AUTOSAR XML (schema 00048)
package /ComponentTypes
  swc implementation SecOc_Server_Implementation: behavior=SecOc_Server_InternalBehavior
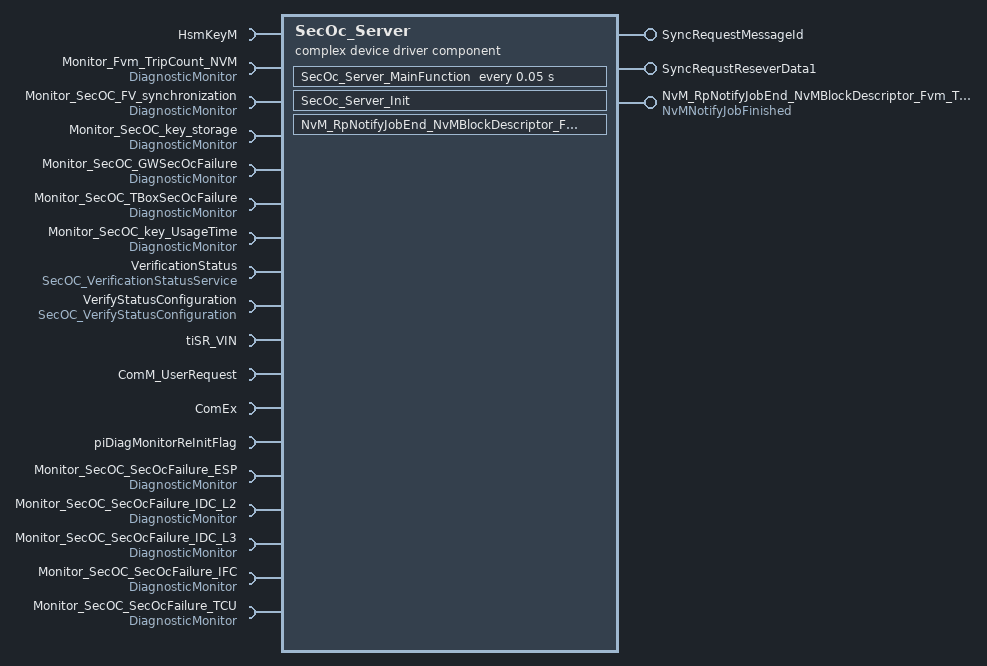
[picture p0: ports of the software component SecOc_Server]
  complex device driver sw component type SecOc_Server
    require port HsmKeyM: required-com-specs=[SetCmacKey, SetAes128Key, GetCmacKeyState, GetCmacKey, GetAes128Key], required-interface=HsmKeyM
    provide port SyncRequestMessageId: nonqueued-sender-com-spec{data-element=SyncRequestMessageId, init-value=17}, provided-interface=SyncRequestMessageId
    provide port SyncRequstReseverData1: nonqueued-sender-com-spec{data-element=SyncRequstReseverData1, init-value=7 x 0}, provided-interface=SyncRequstReseverData1
    require port Monitor_Fvm_TripCount_NVM: required-interface=DiagnosticMonitor
      required-com-specs:
        GetEventExtendedDataRecordEx
        GetEventFreezeFrameDataEx
        GetFaultDetectionCounter
        GetDTCOfEvent
        GetEventTested
        GetEventFailed
        GetEventStatus
        GetEventUdsStatus
        ResetEventDebounceStatus
        ResetEventStatus
        SetEventStatus
    provide port NvM_RpNotifyJobEnd_NvMBlockDescriptor_Fvm_TripCount: server-com-spec{operation=JobFinished, queue-length=1}, provided-interface=NvMNotifyJobFinished
    16 x require port:
      Monitor_SecOC_FV_synchronization: required-interface=DiagnosticMonitor
        required-com-specs:
          GetEventExtendedDataRecordEx
          GetEventFreezeFrameDataEx
          GetFaultDetectionCounter
          GetDTCOfEvent
          GetEventTested
          GetEventFailed
          GetEventStatus
          GetEventUdsStatus
          ResetEventDebounceStatus
          ResetEventStatus
          SetEventStatus
      Monitor_SecOC_key_storage: required-interface=DiagnosticMonitor
        required-com-specs:
          GetEventExtendedDataRecordEx
          GetEventFreezeFrameDataEx
          GetFaultDetectionCounter
          GetDTCOfEvent
          GetEventTested
          GetEventFailed
          GetEventStatus
          GetEventUdsStatus
          ResetEventDebounceStatus
          ResetEventStatus
          SetEventStatus
      Monitor_SecOC_GWSecOcFailure: required-interface=DiagnosticMonitor
        required-com-specs:
          GetEventExtendedDataRecordEx
          GetEventFreezeFrameDataEx
          GetFaultDetectionCounter
          GetDTCOfEvent
          GetEventTested
          GetEventFailed
          GetEventStatus
          GetEventUdsStatus
          ResetEventDebounceStatus
          ResetEventStatus
          SetEventStatus
      Monitor_SecOC_TBoxSecOcFailure: required-interface=DiagnosticMonitor
        required-com-specs:
          GetEventExtendedDataRecordEx
          GetEventFreezeFrameDataEx
          GetFaultDetectionCounter
          GetDTCOfEvent
          GetEventTested
          GetEventFailed
          GetEventStatus
          GetEventUdsStatus
          ResetEventDebounceStatus
          ResetEventStatus
          SetEventStatus
      Monitor_SecOC_key_UsageTime: required-interface=DiagnosticMonitor
        required-com-specs:
          GetEventExtendedDataRecordEx
          GetEventFreezeFrameDataEx
          GetFaultDetectionCounter
          GetDTCOfEvent
          GetEventTested
          GetEventFailed
          GetEventStatus
          GetEventUdsStatus
          ResetEventDebounceStatus
          ResetEventStatus
          SetEventStatus
      VerificationStatus: nonqueued-receiver-com-spec=data-element=verificationStatus, required-interface=SecOC_VerificationStatusService
      VerifyStatusConfiguration: client-com-spec=VerifyStatusOverride, required-interface=SecOC_VerifyStatusConfiguration
      tiSR_VIN: nonqueued-receiver-com-spec{data-element=Element, filter=data-filter-type=ALWAYS, init-value=17 x 0}, required-interface=tiSR_VIN
      ComM_UserRequest: required-com-specs=[GetRequestedComMode, GetMaxComMode, GetCurrentComMode, RequestComMode], required-interface=ComM_UserRequest
      ComEx: required-com-specs=[SendSignal, ReceiveSignal, GetRxE2EStatus], required-interface=ComEx
      piDiagMonitorReInitFlag: nonqueued-receiver-com-spec{data-element=ChangeCounter, filter=data-filter-type=ALWAYS}, required-interface=piDiagMonitorReInitFlag
      Monitor_SecOC_SecOcFailure_ESP: required-interface=DiagnosticMonitor
        required-com-specs:
          SetEventStatus
          ResetEventStatus
          ResetEventDebounceStatus
          GetEventUdsStatus
          GetEventStatus
          GetEventFailed
          GetEventTested
          GetDTCOfEvent
          GetFaultDetectionCounter
          GetEventFreezeFrameDataEx
          GetEventExtendedDataRecordEx
      Monitor_SecOC_SecOcFailure_IDC_L2: required-interface=DiagnosticMonitor
        required-com-specs:
          SetEventStatus
          ResetEventStatus
          ResetEventDebounceStatus
          GetEventUdsStatus
          GetEventStatus
          GetEventFailed
          GetEventTested
          GetDTCOfEvent
          GetFaultDetectionCounter
          GetEventFreezeFrameDataEx
          GetEventExtendedDataRecordEx
      Monitor_SecOC_SecOcFailure_IDC_L3: required-interface=DiagnosticMonitor
        required-com-specs:
          SetEventStatus
          ResetEventStatus
          ResetEventDebounceStatus
          GetEventUdsStatus
          GetEventStatus
          GetEventFailed
          GetEventTested
          GetDTCOfEvent
          GetFaultDetectionCounter
          GetEventFreezeFrameDataEx
          GetEventExtendedDataRecordEx
      Monitor_SecOC_SecOcFailure_IFC: required-interface=DiagnosticMonitor
        required-com-specs:
          SetEventStatus
          ResetEventStatus
          ResetEventDebounceStatus
          GetEventUdsStatus
          GetEventStatus
          GetEventFailed
          GetEventTested
          GetDTCOfEvent
          GetFaultDetectionCounter
          GetEventFreezeFrameDataEx
          GetEventExtendedDataRecordEx
      Monitor_SecOC_SecOcFailure_TCU: required-interface=DiagnosticMonitor
        required-com-specs:
          SetEventStatus
          ResetEventStatus
          ResetEventDebounceStatus
          GetEventUdsStatus
          GetEventStatus
          GetEventFailed
          GetEventTested
          GetDTCOfEvent
          GetFaultDetectionCounter
          GetEventFreezeFrameDataEx
          GetEventExtendedDataRecordEx
    behavior SecOc_Server_InternalBehavior
      init event SecOc_Server_InitEvent: start-on-event=SecOc_Server_Init
      timing event TMT_SecOc_Server_MainFunction: start-on-event=SecOc_Server_MainFunction, period=0.05
      operation invoked event OIT_NvM_RpNotifyJobEnd_NvMBlockDescriptor_Fvm_TripCount_JobFinished_NvM_RpNotifyJobEnd_NvMBlockDescriptor_Fvm_TripCount_8A546D20: start-on-event=NvM_RpNotifyJobEnd_NvMBlockDescriptor_Fvm_TripCount_JobFinished, operation=NvM_RpNotifyJobEnd_NvMBlockDescriptor_Fvm_TripCount.JobFinished
      runnable SecOc_Server_Init
      runnable SecOc_Server_MainFunction
        data-receive-point-by-arguments:
          access REC_VerificationStatus_verificationStatus: accessed-variable=VerificationStatus.verificationStatus
          access REC_tiSR_VIN_Element: accessed-variable=tiSR_VIN.Element
          access REC_piDiagMonitorReInitFlag_ChangeCounter: accessed-variable=piDiagMonitorReInitFlag.ChangeCounter
        data-send-points:
          access SEND_SyncRequestMessageId_SyncRequestMessageId: accessed-variable=SyncRequestMessageId.SyncRequestMessageId
          access SEND_SyncRequstReseverData1_SyncRequstReseverData1: accessed-variable=SyncRequstReseverData1.SyncRequstReseverData1
        17 x sync call:
          SC_HsmKeyM_GetCmacKey: operation=HsmKeyM.GetCmacKey
          SC_HsmKeyM_GetCmacKeyState: operation=HsmKeyM.GetCmacKeyState
          SC_HsmKeyM_SetCmacKey: operation=HsmKeyM.SetCmacKey
          SC_Monitor_Fvm_TripCount_NVM_SetEventStatus: operation=Monitor_Fvm_TripCount_NVM.SetEventStatus
          SC_Monitor_SecOC_FV_synchronization_SetEventStatus: operation=Monitor_SecOC_FV_synchronization.SetEventStatus
          SC_Monitor_SecOC_TBoxSecOcFailure_SetEventStatus: operation=Monitor_SecOC_TBoxSecOcFailure.SetEventStatus
          SC_Monitor_SecOC_key_UsageTime_SetEventStatus: operation=Monitor_SecOC_key_UsageTime.SetEventStatus
          SC_Monitor_SecOC_key_storage_SetEventStatus: operation=Monitor_SecOC_key_storage.SetEventStatus
          SC_Monitor_SecOC_GWSecOcFailure_SetEventStatus: operation=Monitor_SecOC_GWSecOcFailure.SetEventStatus
          SC_VerifyStatusConfiguration_VerifyStatusOverride: operation=VerifyStatusConfiguration.VerifyStatusOverride
          SC_ComM_UserRequest_GetCurrentComMode: operation=ComM_UserRequest.GetCurrentComMode
          SC_ComEx_SendSignal: operation=ComEx.SendSignal
          SC_Event_SecOC_Security_PDU_Verification_Failed_from_ESP_SetEventStatus: operation=Monitor_SecOC_SecOcFailure_ESP.SetEventStatus
          SC_Event_SecOC_Security_PDU_Verification_Failed_from_IDC_L2_SetEventStatus: operation=Monitor_SecOC_SecOcFailure_IDC_L2.SetEventStatus
          SC_Event_SecOC_Security_PDU_Verification_Failed_from_IDC_L3_SetEventStatus: operation=Monitor_SecOC_SecOcFailure_IDC_L3.SetEventStatus
          SC_Event_SecOC_Security_PDU_Verification_Failed_from_IFC_SetEventStatus: operation=Monitor_SecOC_SecOcFailure_IFC.SetEventStatus
          SC_Event_SecOC_Security_PDU_Verification_Failed_from_TCU_SetEventStatus: operation=Monitor_SecOC_SecOcFailure_TCU.SetEventStatus
      runnable NvM_RpNotifyJobEnd_NvMBlockDescriptor_Fvm_TripCount_JobFinished
